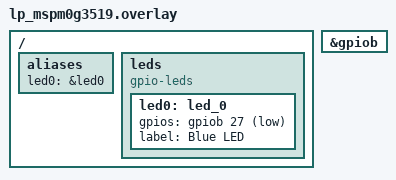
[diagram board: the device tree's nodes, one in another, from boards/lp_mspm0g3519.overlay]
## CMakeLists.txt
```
# SPDX-License-Identifier: Apache-2.0

cmake_minimum_required(VERSION 3.20.0)
find_package(Zephyr REQUIRED HINTS $ENV{ZEPHYR_BASE})
project(blinky)
FILE(GLOB app_sources src/*.c src/Display/*.c)
target_sources(app PRIVATE ${app_sources})
zephyr_compile_options(-mcmse)
zephyr_compile_options(-D__SAUREGION_PRESENT -DCONFIG_CPU_HAS_ARM_SAU)
zephyr_library_include_directories(${ZEPHYR_BASE}/samples/basic/blinky ${ZEPHYR_BASE}/samples/basic/blinky/src/Display /home/mspm33_SDK/msp-sdk/source/ /home/mspm33_SDK/msp-sdk//source/third_party/CMSIS/Core/Include/)
```

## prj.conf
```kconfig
CONFIG_GPIO=y
CONFIG_XIP=y
CONFIG_HAVE_CUSTOM_LINKER_SCRIPT=y
CONFIG_CUSTOM_LINKER_SCRIPT="mylinker.cmd"
CONFIG_GEN_ISR_TABLES=n
CONFIG_DYNAMIC_INTERRUPTS=y
# Enable UART driver
CONFIG_SERIAL=y
# Enable Console
CONFIG_CONSOLE=y
CONFIG_UART_CONSOLE=y
CONFIG_PRINTK=y
```

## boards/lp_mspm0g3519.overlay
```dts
/* SPDX-License-Identifier: Apache-2.0 */


/ {
	aliases {
		led0 = &led0;
	};

	leds {
		compatible = "gpio-leds";

		led0: led_0 {
			gpios = <&gpiob 27 GPIO_ACTIVE_LOW>;
			label = "Blue LED";
		};
	};
};

&gpiob {
	status = "okay";
};
```

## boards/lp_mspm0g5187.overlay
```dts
/* SPDX-License-Identifier: Apache-2.0 */

/ {
	aliases {
		led0 = &led0;
	};

	leds {
		compatible = "gpio-leds";

		led0: led_0 {
			gpios = <&gpiob 13 GPIO_ACTIVE_HIGH>;
			label = "Red LED";
		};
	};
};

&gpiob {
	status = "okay";
};
```

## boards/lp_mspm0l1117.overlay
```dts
/* SPDX-License-Identifier: Apache-2.0 */

/ {
	aliases {
		led0 = &led0;
	};

	leds {
		compatible = "gpio-leds";

		led0: led_0 {
			gpios = <&gpiob 16 GPIO_ACTIVE_HIGH>;
			label = "Red LED";
		};
	};
};

&gpiob {
	status = "okay";
};
```

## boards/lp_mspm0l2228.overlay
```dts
/* SPDX-License-Identifier: Apache-2.0 */

/ {
	aliases {
		led0 = &led0;
	};

	leds {
		compatible = "gpio-leds";

		led0: led_0 {
			gpios = <&gpiob 10 GPIO_ACTIVE_HIGH>;
			label = "Red LED";
		};
	};
};

&gpiob {
	status = "okay";
};
```

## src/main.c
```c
/*
 * Copyright (c) 2016 Intel Corporation
 *
 * SPDX-License-Identifier: Apache-2.0
 */

#include <stdio.h>
#include <string.h>
#include <zephyr/kernel.h>
#include <zephyr/drivers/gpio.h>
#include "ti_msp_dl_config.h"

/* GrLib Includes */
#include "grlib.h"
#include "button.h"
#include "imageButton.h"
#include "radioButton.h"
#include "checkbox.h"
#include "kitronix320x240x16_ssd2119_spi.h"
#include "images.h"
#include "core_cm33.h"
//#include "touch_P401R.h"

/* 1000 msec = 1 sec */
#define SLEEP_TIME_MS   1000

/* The devicetree node identifier for the "led0" alias. */
#define LED0_NODE DT_ALIAS(led0)

/* size of stack area used by each thread */
#define STACKSIZE 1024

/* scheduling priority used by each thread */
#define PRIORITY 7

char *boot_str = "M33 Zephyr is Alive";
char *t1_str = "Zephyr Thread 1";
char *t2_str = "Zephyr Thread 2";
//void drawTiLogo(char *);
void drawTiLogo(Graphics_Context *ctx, char *str);

bool led_state = true;
// Graphic library context
Graphics_Context g_sContext;
Graphics_Context g_sContext1;
Graphics_Context g_sContext2;
/*
 * A build error on this line means your board is unsupported.
 * See the sample documentation for information on how to fix this.
 */
static const struct gpio_dt_spec led = GPIO_DT_SPEC_GET(LED0_NODE, gpios);

K_SEM_DEFINE(my_sem, 0, 1);

void blink0(void)
{
  uint8_t ret = 0;

  k_sched_lock();
  Kitronix320x240x16_SSD2119Init();
  Graphics_initContext(&g_sContext1, &g_sKitronix320x240x16_SSD2119);
  Graphics_setBackgroundColor(&g_sContext1, GRAPHICS_COLOR_BLACK);
  Graphics_setFont(&g_sContext1, &g_sFontCmss20b);
  Graphics_clearDisplay(&g_sContext1);
  k_sched_unlock();

  while(1) {

    k_sched_lock();
    drawTiLogo(&g_sContext1, t1_str);
    k_sched_unlock();

    gpio_pin_toggle_dt(&led);
    k_msleep(1000);
    gpio_pin_toggle_dt(&led);

    led_state = !led_state;
    printf("LED state: %s\n", led_state ? "ON" : "OFF");
    printk("Hello from blink0 thread!\n");
    k_msleep(1000);
    //k_sem_give(&my_sem);
  }
}

void blink1(void)
{

  uint8_t ret = 0;

  k_sched_lock();
  Kitronix320x240x16_SSD2119Init();
  Graphics_initContext(&g_sContext2, &g_sKitronix320x240x16_SSD2119);
  Graphics_setBackgroundColor(&g_sContext2, GRAPHICS_COLOR_BLACK);
  Graphics_setFont(&g_sContext2, &g_sFontCmss20b);
  Graphics_clearDisplay(&g_sContext2);
  k_sched_unlock();
  while(1) {
    //while(k_sem_take(&mDL_UNICOMM_SPIy_sem, K_MSEC(50)) != 0);

    k_sched_lock();
    drawTiLogo(&g_sContext2, t2_str);
    k_sched_unlock();

    DL_GPIO_initDigitalOutput(GPIO_LEDS_USER_LED_1_IOMUX);
    DL_GPIO_togglePins(GPIOC, GPIO_LEDS_USER_LED_1_PIN);
    k_msleep(1000);
    DL_GPIO_togglePins(GPIOC, GPIO_LEDS_USER_LED_1_PIN);
#if 0
    gpio_pin_toggle_dt(&led);
    k_msleep(1000);
    gpio_pin_toggle_dt(&led);
#endif

    led_state = !led_state;
    printk("Hello from blink1 thread!\n");
    printf("LED state: %s\n", led_state ? "ON" : "OFF");
    k_msleep(1000);
  }
}

K_THREAD_DEFINE(blink0_id, STACKSIZE, blink0, NULL, NULL, NULL,
    PRIORITY, 0, 0);
K_THREAD_DEFINE(blink1_id, STACKSIZE, blink1, NULL, NULL, NULL,
    PRIORITY, 0, 0);



/*
 * Number of bytes for SPI packet size
 * The packet will be transmitted by the SPI controller.
 * This example uses FIFOs with polling, and the maximum FIFO size is 4.
 * Refer to interrupt examples to handle larger packets.
 */
#define SPI_PACKET_SIZE (4)

/* Data for SPI to transmit */
uint8_t gTxPacket[SPI_PACKET_SIZE] = {'M', 'S', 'P', '!'};

/* Data received from SPI Peripheral */
volatile uint8_t gRxPacket[SPI_PACKET_SIZE];



void drawTiLogo( Graphics_Context *ctx, char *str)
{
  Graphics_setForegroundColor(ctx, GRAPHICS_COLOR_RED);
  Graphics_setBackgroundColor(ctx, GRAPHICS_COLOR_BLACK);
  Graphics_clearDisplay(ctx);
  //Graphics_drawStringCentered(&g_sContext, "MSP M33 Graphics Library Demo",
  //Graphics_drawStringCentered(&g_sContext, "MSP M33C321A Graphics Library Demo",
    Graphics_drawStringCentered(ctx, (char*)str,
        //AUTO_STRING_LENGTH,
        strlen(str),
        159,
        15,
        TRANSPARENT_TEXT);

  // Draw TI banner at the bottom of screnn
  Graphics_drawImage(ctx,
      &TI_platform_bar_red4BPP_UNCOMP,
      0,
      Graphics_getDisplayHeight(
        ctx) - TI_platform_bar_red4BPP_UNCOMP.ySize);

  //Draw TI Logo
  Graphics_drawImage(ctx,
      &TI_logo_150x1501BPP_COMP_RLE4,
      85,
      45);

  //    // Draw Primitives image button
  //    Graphics_drawImageButton(&g_sContext, &primitiveButton);
  //
  //    // Draw Images image button
  //    Graphics_drawImageButton(&g_sContext, &imageButton);
}

/*******************************************************************************
 * Definitions
 ******************************************************************************/
#define TZM_IS_NONSECURE_CALLED __attribute__((cmse_nonsecure_call))
#define TZM_IS_NOSECURE_ENTRY   __attribute__((cmse_nonsecure_entry))
/* typedef for non-secure callback functions */
typedef void (*funcptr_ns)(void) TZM_IS_NONSECURE_CALLED;

/*******************************************************************************
 * Prototypes
 ******************************************************************************/

/*******************************************************************************
 * Code
 ******************************************************************************/
/*!
 * @brief This function jumps to normal world.
 */
void TZM_JumpToNormalWorld(uint32_t nonsecVtorAddress)
{
    funcptr_ns ResetHandler_ns;

    /* Set non-secure main stack (MSP_NS) */
    __TZ_set_MSP_NS(*((uint32_t *)(nonsecVtorAddress)));

    /* Set non-secure vector table */
    SCB_NS->VTOR = nonsecVtorAddress;

    /* Get non-secure reset handler */
    ResetHandler_ns = (funcptr_ns)(*((uint32_t *)((nonsecVtorAddress) + 4U)));

#if defined(IAR_FP_VLSTM_ALIGNED_ISSUE) && (IAR_FP_VLSTM_ALIGNED_ISSUE == 1U) && defined(__ICCARM__)
#define COMPILER_VERSION_MAJOR ((__VER__) / 1000000)
#define COMPILER_VERSION_MINOR (((__VER__) / 1000) % 1000)
#if (COMPILER_VERSION_MAJOR == 9) && (COMPILER_VERSION_MINOR < 32)
    {
        /*
         * IAR issue: in ResetHandler_ns asm code, only push 7 register into stack
         * for Armv8-M, Stack pointer need aligned with 8bytes, otherwise will triger
         * a exception.
         * After IAR (9.32) fixed this issue ,this code must be deleted.
         */

        register unsigned int tmpSp;
        int byteAlign;

        asm volatile("MOV %0, SP\n" : "=r"(tmpSp));

        /* One register size is 4byte */
        tmpSp = (tmpSp % 32) / 4;
        for (byteAlign = 0; (byteAlign + tmpSp + 7) % 8 != 0; byteAlign++)
        {
            asm volatile("PUSH {r12}");
        }
    }
#endif
#endif
    /* Call non-secure application - jump to normal world */
    ResetHandler_ns();
#if defined(IAR_FP_VLSTM_ALIGNED_ISSUE) && (IAR_FP_VLSTM_ALIGNED_ISSUE == 1U) && defined(__ICCARM__)
    {
        /* Never return here, so do not need 'POP' */
    }
#endif
}
#define SAU_REGION_0_BASE 0x10080000U
#define SAU_REGION_0_END  0x10100000U
void BOARD_InitTrustZone()
{
    /* SAU configuration */

    /* Set SAU Control register: Disable SAU and All Secure */
    SAU->CTRL = 0;


    /* Set SAU region number */
    SAU->RNR = 0;
    /* Region base address */
    SAU->RBAR = SAU_REGION_0_BASE & SAU_RBAR_BADDR_Msk;
    /* Region end address */
    SAU->RLAR = (SAU_REGION_0_END & SAU_RLAR_LADDR_Msk) | ((0U << SAU_RLAR_NSC_Pos) & SAU_RLAR_NSC_Msk) |
                ((1U << SAU_RLAR_ENABLE_Pos) & SAU_RLAR_ENABLE_Msk);
    /* Force memory writes before continuing */
    __DSB();
    /* Flush and refill pipeline with updated permissions */
    __ISB();

    /* Set SAU Control register: Enable SAU and All Secure (applied only if disabled) */
    SAU->CTRL = ((0U << SAU_CTRL_ALLNS_Pos) & SAU_CTRL_ALLNS_Msk) | ((1U << SAU_CTRL_ENABLE_Pos) & SAU_CTRL_ENABLE_Msk);
}

#define NON_SECURE_START 0x10080000

int main(void)
{
	int ret;

  BOARD_InitTrustZone();

  SYSCFG_DL_init();

	if (!gpio_is_ready_dt(&led)) {
		return 0;
	}

	ret = gpio_pin_configure_dt(&led, GPIO_OUTPUT_ACTIVE);
	if (ret < 0) {
		return 0;
	}

  // LCD setup using Graphics Library API calls
  Kitronix320x240x16_SSD2119Init();
  Graphics_initContext(&g_sContext, &g_sKitronix320x240x16_SSD2119);
  Graphics_setBackgroundColor(&g_sContext, GRAPHICS_COLOR_BLACK);
  Graphics_setFont(&g_sContext, &g_sFontCmss20b);
  Graphics_clearDisplay(&g_sContext);

  //Draw TI Logo
  drawTiLogo(&g_sContext, boot_str);
  k_msleep(3000);
  while(1) {
    k_msleep(SLEEP_TIME_MS);
  }
  #if 0
  while(1) {
    ret = gpio_pin_toggle_dt(&led);
    if (ret < 0) {
      return 0;
    }

    led_state = !led_state;
    printf("LED state: %s\n", led_state ? "ON" : "OFF");
    k_msleep(SLEEP_TIME_MS);
  }
  #endif

  //TZM_JumpToNormalWorld(NON_SECURE_START);

	//return 0;
}
```

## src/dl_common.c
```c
/*
 * Copyright (c) 2020, Texas Instruments Incorporated
 * All rights reserved.
 *
 * Redistribution and use in source and binary forms, with or without
 * modification, are permitted provided that the following conditions
 * are met:
 *
 * *  Redistributions of source code must retain the above copyright
 *    notice, this list of conditions and the following disclaimer.
 *
 * *  Redistributions in binary form must reproduce the above copyright
 *    notice, this list of conditions and the following disclaimer in the
 *    documentation and/or other materials provided with the distribution.
 *
 * *  Neither the name of Texas Instruments Incorporated nor the names of
 *    its contributors may be used to endorse or promote products derived
 *    from this software without specific prior written permission.
 *
 * THIS SOFTWARE IS PROVIDED BY THE COPYRIGHT HOLDERS AND CONTRIBUTORS "AS IS"
 * AND ANY EXPRESS OR IMPLIED WARRANTIES, INCLUDING, BUT NOT LIMITED TO,
 * THE IMPLIED WARRANTIES OF MERCHANTABILITY AND FITNESS FOR A PARTICULAR
 * PURPOSE ARE DISCLAIMED. IN NO EVENT SHALL THE COPYRIGHT OWNER OR
 * CONTRIBUTORS BE LIABLE FOR ANY DIRECT, INDIRECT, INCIDENTAL, SPECIAL,
 * EXEMPLARY, OR CONSEQUENTIAL DAMAGES (INCLUDING, BUT NOT LIMITED TO,
 * PROCUREMENT OF SUBSTITUTE GOODS OR SERVICES; LOSS OF USE, DATA, OR PROFITS;
 * OR BUSINESS INTERRUPTION) HOWEVER CAUSED AND ON ANY THEORY OF LIABILITY,
 * WHETHER IN CONTRACT, STRICT LIABILITY, OR TORT (INCLUDING NEGLIGENCE OR
 * OTHERWISE) ARISING IN ANY WAY OUT OF THE USE OF THIS SOFTWARE,
 * EVEN IF ADVISED OF THE POSSIBILITY OF SUCH DAMAGE.
 */

#include <stdint.h>

#include <ti/driverlib/dl_common.h>
#if 0
void DL_Common_delayCycles(uint32_t cycles)
{
    /* this is a scratch register for the compiler to use */
    uint32_t scratch;

    /* There will be a 2 cycle delay here to fetch & decode instructions
     * if branch and linking to this function */

    /* Subtract 2 net cycles for constant offset: +2 cycles for entry jump,
     * +2 cycles for exit, -1 cycle for a shorter loop cycle on the last loop,
     * -1 for this instruction */

    __asm volatile(
#ifdef __GNUC__
        ".syntax unified\n\t"
#endif
        "SUBS %0, %[numCycles], #2; \n"
        "%=: \n\t"
        "SUBS %0, %0, #4; \n\t"
        "NOP; \n\t"
        "BHS  %=b;" /* branches back to the label defined above if number > 0 */
        /* Return: 2 cycles */
        : "=&r"(scratch)
        : [ numCycles ] "r"(cycles));
}
#endif
```

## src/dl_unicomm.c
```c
/*
 * Copyright (c) 2025, Texas Instruments Incorporated
 * All rights reserved.
 *
 * Redistribution and use in source and binary forms, with or without
 * modification, are permitted provided that the following conditions
 * are met:
 *
 * *  Redistributions of source code must retain the above copyright
 *    notice, this list of conditions and the following disclaimer.
 *
 * *  Redistributions in binary form must reproduce the above copyright
 *    notice, this list of conditions and the following disclaimer in the
 *    documentation and/or other materials provided with the distribution.
 *
 * *  Neither the name of Texas Instruments Incorporated nor the names of
 *    its contributors may be used to endorse or promote products derived
 *    from this software without specific prior written permission.
 *
 * THIS SOFTWARE IS PROVIDED BY THE COPYRIGHT HOLDERS AND CONTRIBUTORS "AS IS"
 * AND ANY EXPRESS OR IMPLIED WARRANTIES, INCLUDING, BUT NOT LIMITED TO,
 * THE IMPLIED WARRANTIES OF MERCHANTABILITY AND FITNESS FOR A PARTICULAR
 * PURPOSE ARE DISCLAIMED. IN NO EVENT SHALL THE COPYRIGHT OWNER OR
 * CONTRIBUTORS BE LIABLE FOR ANY DIRECT, INDIRECT, INCIDENTAL, SPECIAL,
 * EXEMPLARY, OR CONSEQUENTIAL DAMAGES (INCLUDING, BUT NOT LIMITED TO,
 * PROCUREMENT OF SUBSTITUTE GOODS OR SERVICES; LOSS OF USE, DATA, OR PROFITS;
 * OR BUSINESS INTERRUPTION) HOWEVER CAUSED AND ON ANY THEORY OF LIABILITY,
 * WHETHER IN CONTRACT, STRICT LIABILITY, OR TORT (INCLUDING NEGLIGENCE OR
 * OTHERWISE) ARISING IN ANY WAY OUT OF THE USE OF THIS SOFTWARE,
 * EVEN IF ADVISED OF THE POSSIBILITY OF SUCH DAMAGE.
 */

#include "dl_unicomm.h"

#ifdef __MCU_HAS_UNICOMM__
#endif /* __MCU_HAS_UNICOMM__ */
```

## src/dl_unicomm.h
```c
/*
 * Copyright (c) 2024, Texas Instruments Incorporated
 * All rights reserved.
 *
 * Redistribution and use in source and binary forms, with or without
 * modification, are permitted provided that the following conditions
 * are met:
 *
 * *  Redistributions of source code must retain the above copyright
 *    notice, this list of conditions and the following disclaimer.
 *
 * *  Redistributions in binary form must reproduce the above copyright
 *    notice, this list of conditions and the following disclaimer in the
 *    documentation and/or other materials provided with the distribution.
 *
 * *  Neither the name of Texas Instruments Incorporated nor the names of
 *    its contributors may be used to endorse or promote products derived
 *    from this software without specific prior written permission.
 *
 * THIS SOFTWARE IS PROVIDED BY THE COPYRIGHT HOLDERS AND CONTRIBUTORS "AS IS"
 * AND ANY EXPRESS OR IMPLIED WARRANTIES, INCLUDING, BUT NOT LIMITED TO,
 * THE IMPLIED WARRANTIES OF MERCHANTABILITY AND FITNESS FOR A PARTICULAR
 * PURPOSE ARE DISCLAIMED. IN NO EVENT SHALL THE COPYRIGHT OWNER OR
 * CONTRIBUTORS BE LIABLE FOR ANY DIRECT, INDIRECT, INCIDENTAL, SPECIAL,
 * EXEMPLARY, OR CONSEQUENTIAL DAMAGES (INCLUDING, BUT NOT LIMITED TO,
 * PROCUREMENT OF SUBSTITUTE GOODS OR SERVICES; LOSS OF USE, DATA, OR PROFITS;
 * OR BUSINESS INTERRUPTION) HOWEVER CAUSED AND ON ANY THEORY OF LIABILITY,
 * WHETHER IN CONTRACT, STRICT LIABILITY, OR TORT (INCLUDING NEGLIGENCE OR
 * OTHERWISE) ARISING IN ANY WAY OUT OF THE USE OF THIS SOFTWARE,
 * EVEN IF ADVISED OF THE POSSIBILITY OF SUCH DAMAGE.
 */
/*!****************************************************************************
 *  @file       dl_unicomm.h
 *  @brief      Universal Serial Communication (UNICOMM) Driver Library
 *  @defgroup   UNICOMM Universal Serial Communication (UNICOMM)
 *
 *  @anchor ti_dl_dl_m0p_unicomm_Overview
 *  # Overview
 *
 *  TODO
 *
 *  <hr>
 ******************************************************************************
 */
/** @addtogroup UNICOMM
 * @{
 */
#ifndef ti_dl_dl_unicomm__include
#define ti_dl_dl_unicomm__include

#include <stdbool.h>
#include <stdint.h>

#include <ti/devices/msp/msp.h>
#include <ti/driverlib/dl_common.h>


#ifdef __cplusplus
extern "C" {
#endif

/* clang-format off */

/*! @enum DL_UNICOMM_IP_MODE_SEL */
typedef enum {
    /*! Select UART functionality */
    DL_UNICOMM_UART = UNICOMM_IPMODE_SELECT_UART,
    /*! Select SPI functionality*/
    DL_UNICOMM_SPI = UNICOMM_IPMODE_SELECT_SPI,
    /*! Select I2C functionality in controller mode */
    DL_UNICOMM_I2C_CONTROLLER = UNICOMM_IPMODE_SELECT_I2C_CONTROLLER,
    /*! Select I2C functionality in target mode */
    DL_UNICOMM_I2C_TARGET = UNICOMM_IPMODE_SELECT_I2C_PERIPHERAL,
} DL_UNICOMM_IP_MODE_SEL;

/**
 *  @brief Enables power on unicomm module
 *
 *  @param unicomm        Pointer to the register overlay for the peripheral
 */
__STATIC_INLINE void DL_UNICOMM_enablePower(UNICOMM_Inst_Regs *unicomm)
{
    unicomm->inst->GPRCM.PWREN =
        (UNICOMM_PWREN_KEY_UNLOCK_W | UNICOMM_PWREN_ENABLE_ENABLE);
}

/**
 *  @brief Disables power on unicomm module
 *
 *  @param unicomm        Pointer to the register overlay for the peripheral
 */
__STATIC_INLINE void DL_UNICOMM_disablePower(UNICOMM_Inst_Regs *unicomm)
{
    unicomm->inst->GPRCM.PWREN =
        (UNICOMM_PWREN_KEY_UNLOCK_W | UNICOMM_PWREN_ENABLE_DISABLE);
}

/**
 *  @brief Returns if  power on unicomm module
 *
 *  @param unicomm        Pointer to the register overlay for the peripheral
 *
 *  @return true if power is enabled
 *  @return false if power is disabled
 */
__STATIC_INLINE bool DL_UNICOMM_isPowerEnabled(UNICOMM_Inst_Regs *unicomm)
{
    return ((unicomm->inst->GPRCM.PWREN & UNICOMM_PWREN_ENABLE_MASK) ==
            UNICOMM_PWREN_ENABLE_ENABLE);
}

/**
 *  @brief Resets unicomm peripheral
 *
 *  @param unicomm        Pointer to the register overlay for the UNICOMM peripheral
 */
__STATIC_INLINE void DL_UNICOMM_reset(UNICOMM_Inst_Regs *unicomm)
{
    unicomm->inst->GPRCM.RSTCTL =
        (UNICOMM_RSTCTL_KEY_UNLOCK_W | UNICOMM_RSTCTL_RESETSTKYCLR_CLR |
            UNICOMM_RSTCTL_RESETASSERT_ASSERT);
}

/**
 *  @brief Returns if unicomm peripheral was reset
 *
 *  @param unicomm        Pointer to the register overlay for the UNICOMM peripheral
 *
 *  @return true if peripheral was reset
 *  @return false if peripheral wasn't reset
 *
 */
__STATIC_INLINE bool DL_UNICOMM_isReset(UNICOMM_Inst_Regs *unicomm)
{
    return ((unicomm->inst->GPRCM.STAT & UNICOMM_STAT_RESETSTKY_MASK) ==
            UNICOMM_STAT_RESETSTKY_RESET);
}

/**
 *  @brief Configure the unicomm peripheral for specified ip mode
 *
 *  @param unicomm        Pointer to the register overlay for the UNICOMM peripheral
 *  @param ipMode         Specifies IP mode functionality. One of @ref DL_UNICOMM_IP_MODE_SEL
 */
__STATIC_INLINE void DL_UNICOMM_setIPMode(UNICOMM_Inst_Regs *unicomm, DL_UNICOMM_IP_MODE_SEL ipMode)
{
    unicomm->inst->IPMODE = (ipMode & UNICOMM_IPMODE_SELECT_MASK);
}

/**
 *  @brief Returns ip mode the unicomm peripheral is configured to
 *
 *  @param unicomm        Pointer to the register overlay for the UNICOMM peripheral
 *
 *  @return  Configured IP mode selection
 *  @retval  One of @ref DL_UNICOMM_IP_MODE_SEL
 */
__STATIC_INLINE DL_UNICOMM_IP_MODE_SEL DL_UNICOMM_getIPMode(UNICOMM_Inst_Regs *unicomm)
{
    return (DL_UNICOMM_IP_MODE_SEL)(unicomm->inst->IPMODE & UNICOMM_IPMODE_SELECT_MASK);
}

#ifdef __cplusplus
}
#endif


#endif /* ti_dl_dl_unicomm__include */
/** @}*/
```

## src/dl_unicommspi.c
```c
/*
 * Copyright (c) 2025, Texas Instruments Incorporated
 * All rights reserved.
 *
 * Redistribution and use in source and binary forms, with or without
 * modification, are permitted provided that the following conditions
 * are met:
 *
 * *  Redistributions of source code must retain the above copyright
 *    notice, this list of conditions and the following disclaimer.
 *
 * *  Redistributions in binary form must reproduce the above copyright
 *    notice, this list of conditions and the following disclaimer in the
 *    documentation and/or other materials provided with the distribution.
 *
 * *  Neither the name of Texas Instruments Incorporated nor the names of
 *    its contributors may be used to endorse or promote products derived
 *    from this software without specific prior written permission.
 *
 * THIS SOFTWARE IS PROVIDED BY THE COPYRIGHT HOLDERS AND CONTRIBUTORS "AS IS"
 * AND ANY EXPRESS OR IMPLIED WARRANTIES, INCLUDING, BUT NOT LIMITED TO,
 * THE IMPLIED WARRANTIES OF MERCHANTABILITY AND FITNESS FOR A PARTICULAR
 * PURPOSE ARE DISCLAIMED. IN NO EVENT SHALL THE COPYRIGHT OWNER OR
 * CONTRIBUTORS BE LIABLE FOR ANY DIRECT, INDIRECT, INCIDENTAL, SPECIAL,
 * EXEMPLARY, OR CONSEQUENTIAL DAMAGES (INCLUDING, BUT NOT LIMITED TO,
 * PROCUREMENT OF SUBSTITUTE GOODS OR SERVICES; LOSS OF USE, DATA, OR PROFITS;
 * OR BUSINESS INTERRUPTION) HOWEVER CAUSED AND ON ANY THEORY OF LIABILITY,
 * WHETHER IN CONTRACT, STRICT LIABILITY, OR TORT (INCLUDING NEGLIGENCE OR
 * OTHERWISE) ARISING IN ANY WAY OUT OF THE USE OF THIS SOFTWARE,
 * EVEN IF ADVISED OF THE POSSIBILITY OF SUCH DAMAGE.
 */

#include "dl_unicommspi.h"


void DL_SPI_init(UNICOMM_Inst_Regs *unicomm, DL_SPI_Config *config)
{
    DL_Common_updateReg(&unicomm->spi->CTL0,
        (uint32_t) config->chipSelectPin | (uint32_t) config->frameFormat |
            (uint32_t) config->dataSize,
        UNICOMMSPI_CTL0_CSSEL_MASK | UNICOMMSPI_CTL0_FRF_MASK |
            UNICOMMSPI_CTL0_SPO_MASK | UNICOMMSPI_CTL0_SPH_MASK |
            UNICOMMSPI_CTL0_DSS_MASK);

    DL_Common_updateReg(&unicomm->spi->CTL1,
        (uint32_t) config->parity | (uint32_t) config->bitOrder |
            (uint32_t) config->mode,
        UNICOMMSPI_CTL1_PES_MASK | UNICOMMSPI_CTL1_PREN_MASK |
            UNICOMMSPI_CTL1_PTEN_MASK | UNICOMMSPI_CTL1_MSB_MASK |
            UNICOMMSPI_CTL1_CP_MASK);
}

void DL_SPI_setClockConfig(
    UNICOMM_Inst_Regs *unicomm, DL_SPI_ClockConfig *config)
{
    unicomm->spi->CLKSEL = (uint32_t) config->clockSel;

    unicomm->spi->CLKDIV = (uint32_t) config->divideRatio;
}

void DL_SPI_getClockConfig(
    UNICOMM_Inst_Regs *unicomm, DL_SPI_ClockConfig *config)
{
    config->clockSel = (DL_SPI_CLOCK) unicomm->spi->CLKSEL;

    config->divideRatio = (DL_SPI_CLOCK_DIVIDE_RATIO) unicomm->spi->CLKDIV;
}

uint8_t DL_SPI_receiveDataBlocking8(UNICOMM_Inst_Regs *unicomm)
{
    while (DL_SPI_isRXFIFOEmpty(unicomm)) {
    };

    return DL_SPI_receiveData8(unicomm);
}

uint16_t DL_SPI_receiveDataBlocking16(UNICOMM_Inst_Regs *unicomm)
{
    while (DL_SPI_isRXFIFOEmpty(unicomm)) {
    };
    return DL_SPI_receiveData16(unicomm);
}

uint32_t DL_SPI_receiveDataBlocking32(UNICOMM_Inst_Regs *unicomm)
{
    while (DL_SPI_isRXFIFOEmpty(unicomm)) {
    };
    return DL_SPI_receiveData32(unicomm);
}

void DL_SPI_transmitDataBlocking8(UNICOMM_Inst_Regs *unicomm, uint8_t data)
{
    while (DL_SPI_isTXFIFOFull(unicomm)) {
    };
    DL_SPI_transmitData8(unicomm, data);
}

void DL_SPI_transmitDataBlocking16(UNICOMM_Inst_Regs *unicomm, uint16_t data)
{
    while (DL_SPI_isTXFIFOFull(unicomm)) {
    };
    DL_SPI_transmitData16(unicomm, data);
}

void DL_SPI_transmitDataBlocking32(UNICOMM_Inst_Regs *unicomm, uint32_t data)
{
    while (DL_SPI_isTXFIFOFull(unicomm)) {
    };
    DL_SPI_transmitData32(unicomm, data);
}

bool DL_SPI_receiveDataCheck8(UNICOMM_Inst_Regs *unicomm, uint8_t *buffer)
{
    bool status;
    if (DL_SPI_isRXFIFOEmpty(unicomm)) {
        status = false;
    } else {
        *buffer = DL_SPI_receiveData8(unicomm);
        status  = true;
    }

    return status;
}

bool DL_SPI_receiveDataCheck16(UNICOMM_Inst_Regs *unicomm, uint16_t *buffer)
{
    bool status;
    if (DL_SPI_isRXFIFOEmpty(unicomm)) {
        status = false;
    } else {
        *buffer = DL_SPI_receiveData16(unicomm);
        status  = true;
    }

    return status;
}

bool DL_SPI_receiveDataCheck32(UNICOMM_Inst_Regs *unicomm, uint32_t *buffer)
{
    bool status;
    if (DL_SPI_isRXFIFOEmpty(unicomm)) {
        status = false;
    } else {
        *buffer = DL_SPI_receiveData32(unicomm);
        status  = true;
    }

    return status;
}

bool DL_SPI_transmitDataCheck8(UNICOMM_Inst_Regs *unicomm, uint8_t data)
{
    bool status;
    if (DL_SPI_isTXFIFOFull(unicomm)) {
        status = false;
    } else {
        DL_SPI_transmitData8(unicomm, data);
        status = true;
    }

    return status;
}

bool DL_SPI_transmitDataCheck16(UNICOMM_Inst_Regs *unicomm, uint16_t data)
{
    bool status;
    if (DL_SPI_isTXFIFOFull(unicomm)) {
        status = false;
    } else {
        DL_SPI_transmitData16(unicomm, data);
        status = true;
    }

    return status;
}

bool DL_SPI_transmitDataCheck32(UNICOMM_Inst_Regs *unicomm, uint32_t data)
{
    bool status;
    if (DL_SPI_isTXFIFOFull(unicomm)) {
        status = false;
    } else {
        DL_SPI_transmitData32(unicomm, data);
        status = true;
    }

    return status;
}

uint32_t DL_SPI_drainRXFIFO8(
    UNICOMM_Inst_Regs *unicomm, uint8_t *buffer, uint32_t maxCount)
{
    uint32_t i;
    for (i = 0; i < maxCount; i++) {
        if (!DL_SPI_isRXFIFOEmpty(unicomm)) {
            buffer[i] = DL_SPI_receiveData8(unicomm);
        } else {
            break;
        }
    }

    return i;
}

uint32_t DL_SPI_drainRXFIFO16(
    UNICOMM_Inst_Regs *unicomm, uint16_t *buffer, uint32_t maxCount)
{
    uint32_t i;
    for (i = 0; i < maxCount; i++) {
        if (!DL_SPI_isRXFIFOEmpty(unicomm)) {
            buffer[i] = DL_SPI_receiveData16(unicomm);
        } else {
            break;
        }
    }

    return i;
}

uint32_t DL_SPI_drainRXFIFO32(
    UNICOMM_Inst_Regs *unicomm, uint32_t *buffer, uint32_t maxCount)
{
    uint32_t i;
    for (i = 0; i < maxCount; i++) {
        if (!DL_SPI_isRXFIFOEmpty(unicomm)) {
            buffer[i] = DL_SPI_receiveData32(unicomm);
        } else {
            break;
        }
    }

    return i;
}

uint32_t DL_SPI_fillTXFIFO8(
    UNICOMM_Inst_Regs *unicomm, uint8_t *buffer, uint32_t count)
{
    uint32_t i;
    for (i = 0; i < count; i++) {
        if (!DL_SPI_isTXFIFOFull(unicomm)) {
            DL_SPI_transmitData8(unicomm, buffer[i]);
        } else {
            break;
        }
    }

    return i;
}

uint32_t DL_SPI_fillTXFIFO16(
    UNICOMM_Inst_Regs *unicomm, uint16_t *buffer, uint32_t count)
{
    uint32_t i;
    for (i = 0; i < count; i++) {
        if (!DL_SPI_isTXFIFOFull(unicomm)) {
            DL_SPI_transmitData16(unicomm, buffer[i]);
        } else {
            break;
        }
    }

    return i;
}

bool DL_SPI_saveConfiguration(
    UNICOMM_Inst_Regs *unicomm, DL_SPI_backupConfig *ptr)
{
    bool stateSaved = !ptr->backupRdy;
    if (stateSaved) {
        ptr->controlWord0                 = unicomm->spi->CTL0;
        ptr->controlWord1                 = unicomm->spi->CTL1;
        ptr->clockControl                 = unicomm->spi->CLKCTL;
        ptr->clockSel                     = unicomm->spi->CLKSEL;
        ptr->divideRatio                  = unicomm->spi->CLKDIV;
        ptr->interruptFifoLevelSelectWord = unicomm->spi->IFLS;
        ptr->interruptMask0               = unicomm->spi->CPU_INT.IMASK;
        ptr->interruptMask1               = unicomm->spi->DMA_TRIG_RX.IMASK;
        ptr->interruptMask2               = unicomm->spi->DMA_TRIG_TX.IMASK;
        ptr->backupRdy                    = true;
    }
    return stateSaved;
}

bool DL_SPI_restoreConfiguration(
    UNICOMM_Inst_Regs *unicomm, DL_SPI_backupConfig *ptr)
{
    bool stateRestored = ptr->backupRdy;
    if (stateRestored) {
        /* Set CTL1.ENABLE=0 during initialization */
        unicomm->spi->CTL1 =
            ptr->controlWord1 & ~(UNICOMMSPI_CTL1_ENABLE_MASK);
        unicomm->spi->CTL0              = ptr->controlWord0;
        unicomm->spi->CLKCTL            = ptr->clockControl;
        unicomm->spi->CLKSEL            = ptr->clockSel;
        unicomm->spi->CLKDIV            = ptr->divideRatio;
        unicomm->spi->IFLS              = ptr->interruptFifoLevelSelectWord;
        unicomm->spi->CPU_INT.IMASK     = ptr->interruptMask0;
        unicomm->spi->DMA_TRIG_RX.IMASK = ptr->interruptMask1;
        unicomm->spi->DMA_TRIG_TX.IMASK = ptr->interruptMask2;

        /* Re-enable SPI if it was originally enabled */
        if ((ptr->controlWord1 & UNICOMMSPI_CTL1_ENABLE_MASK) ==
            UNICOMMSPI_CTL1_ENABLE_MASK) {
            DL_SPI_enable(unicomm);
        }
        ptr->backupRdy = false;
    }
    return stateRestored;
}

uint32_t DL_SPI_fillTXFIFO32(
    UNICOMM_Inst_Regs *unicomm, uint32_t *buffer, uint32_t count)
{
    uint32_t i;
    for (i = 0; i < count; i++) {
        if (!DL_SPI_isTXFIFOFull(unicomm)) {
            DL_SPI_transmitData32(unicomm, buffer[i]);
        } else {
            break;
        }
    }

    return i;
}
```
